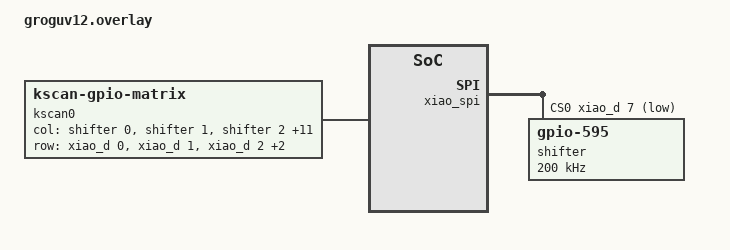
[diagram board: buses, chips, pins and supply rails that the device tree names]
&xiao_spi {
    status = "okay";
    cs-gpios = <&xiao_d 7 GPIO_ACTIVE_LOW>;

    shifter: 595@0 {
        compatible = "zmk,gpio-595";
        status = "okay";
        gpio-controller;
        spi-max-frequency = <200000>;
        reg = <0>;
        #gpio-cells = <2>;
        ngpios = <24>;
    };
};

/ {
    chosen {
        zmk,kscan = &kscan0;
        zmk,matrix-transform = &default_transform;
    };

    default_transform: matrix_transform {
        compatible = "zmk,matrix-transform";
        columns = <14>;
        rows = <5>;
        map = <
            0x0200 0x0301 0x0003 0x0004 0x0005 0x0405 0x010d 0x010c 0x000b 0x000a 0x0009 0x0108
            0x0100 0x0201 0x0302 0x0403 0x0404 0x0305 0x000d 0x000c 0x040a 0x0409 0x0408 0x0008
            0x0000 0x0101 0x0202 0x0303 0x0304 0x0205 0x0206 0x020d 0x030c 0x030b 0x030a 0x0309 0x0308 0x0207
            0x0001 0x0102 0x0203 0x0204 0x0105 0x020c 0x020b 0x020a 0x0209 0x0208
            0x0002 0x0103 0x0104 0x0109 0x010a 0x010b
        >;
    };

    kscan0: kscan_0 {
        compatible = "zmk,kscan-gpio-matrix";
        wakeup-source;
        diode-direction = "col2row";

        col-gpios =
            <&shifter 0  GPIO_ACTIVE_HIGH>
            , <&shifter 1  GPIO_ACTIVE_HIGH>
            , <&shifter 2  GPIO_ACTIVE_HIGH>
            , <&shifter 3  GPIO_ACTIVE_HIGH>
            , <&shifter 4  GPIO_ACTIVE_HIGH>
            , <&shifter 5  GPIO_ACTIVE_HIGH>
            , <&shifter 6  GPIO_ACTIVE_HIGH>
            , <&shifter 7  GPIO_ACTIVE_HIGH>
            , <&shifter 8  GPIO_ACTIVE_HIGH>
            , <&shifter 9  GPIO_ACTIVE_HIGH>
            , <&shifter 10 GPIO_ACTIVE_HIGH>
            , <&shifter 11 GPIO_ACTIVE_HIGH>
            , <&shifter 12 GPIO_ACTIVE_HIGH>
            , <&shifter 13 GPIO_ACTIVE_HIGH>
            ;

        row-gpios =
            <&xiao_d 0 (GPIO_ACTIVE_HIGH | GPIO_PULL_DOWN)>
            , <&xiao_d 1 (GPIO_ACTIVE_HIGH | GPIO_PULL_DOWN)>
            , <&xiao_d 2 (GPIO_ACTIVE_HIGH | GPIO_PULL_DOWN)>
            , <&xiao_d 3 (GPIO_ACTIVE_HIGH | GPIO_PULL_DOWN)>
            , <&xiao_d 4 (GPIO_ACTIVE_HIGH | GPIO_PULL_DOWN)>
            ;
    };
};
